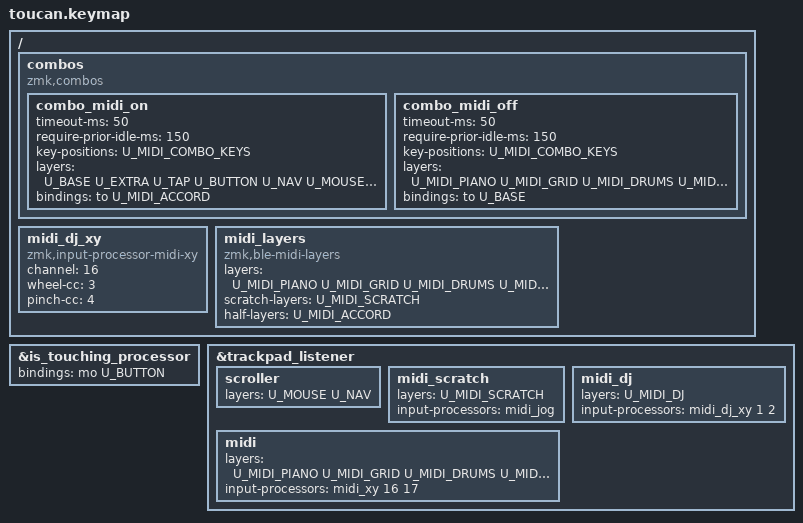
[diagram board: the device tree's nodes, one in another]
// Copyright 2021 Manna Harbour
// https://github.com/manna-harbour/miryoku

// beekeeb Toucan2 (42-key) -- Piantor/Cantor layout with an Azoteq TPS43
// multi-touch trackpad on the RIGHT half.
//
// The key matrix is identical in shape and order to the Corne: 12/12/12 plus
// six thumbs, so the stock Miryoku 42-key Corne mapping applies unchanged,
// including our outer-column Witch / Mouseless / WINDOW keys.

// Bluetooth MIDI: this board builds the zmk-ble-midi module (see
// docs/MIDI.md), which adds the MIDI layers and the midi_* behaviors.
#define MIRYOKU_MIDI
#include <behaviors/midi.dtsi>

#include "../miryoku/custom_config.h"
#include "../miryoku/mapping/42/corne.h"
#include "../miryoku/miryoku_midi.h"
#include "../miryoku/miryoku.dtsi"

// MIDI on / off: press both bottom outer pinky keys together. The same
// gesture enters (always on Accordion) and leaves (back to BASE) from any MIDI
// mode. It is the only way in or out.
//
// Positions 24 and 35 are the bottom-row outer keys (row by row: 12 top,
// 12 home, 12 bottom, 6 thumbs). Normally each one holds the WINDOW layer;
// in the MIDI modes they are notes, drums or Panic / Reset. Alone, every one
// of them still does its own job; the combo only fires when both go down
// within 50 ms. require-prior-idle-ms keeps it out of the way while you
// type or play: if any key was pressed in the last 150 ms, the two keys act
// alone immediately, so fast passages never wait on the combo and can't
// accidentally drop you out of MIDI.
//
// Combos only look at the highest active layer, hence two combos: one for
// the typing layers, one for the MIDI layers (including the held MODE layer).
#define U_MIDI_COMBO_KEYS 24 35
/ {
    combos {
        compatible = "zmk,combos";
        combo_midi_on {
            timeout-ms = <50>;
            require-prior-idle-ms = <150>;
            key-positions = <U_MIDI_COMBO_KEYS>;
            layers = <U_BASE U_EXTRA U_TAP U_BUTTON U_NAV U_MOUSE U_MEDIA U_NUM U_SYM U_FUN U_WINDOW>;
            bindings = <&to U_MIDI_ACCORD>;
        };
        combo_midi_off {
            timeout-ms = <50>;
            require-prior-idle-ms = <150>;
            key-positions = <U_MIDI_COMBO_KEYS>;
            layers = <U_MIDI_PIANO U_MIDI_GRID U_MIDI_DRUMS U_MIDI_CHORD U_MIDI_CTRL U_MIDI_DJ U_MIDI_SCRATCH U_MIDI_ACCORD U_MIDI_MODE>;
            bindings = <&to U_BASE>;
        };
    };

    // Tells the zmk-ble-midi module (and through it the status screen)
    // which layers are MIDI layers, so the screen shows key / octave /
    // velocity / channel there instead of the typing-speed graph.
    // Trackpad processor for the DJ mode (see &trackpad_listener below).
    midi_dj_xy: midi_dj_xy {
        compatible = "zmk,input-processor-midi-xy";
        #input-processor-cells = <2>;
        channel = <16>;
        wheel-cc = <3>;
        pinch-cc = <4>;
    };

    midi_layers {
        compatible = "zmk,ble-midi-layers";
        layers = <U_MIDI_PIANO U_MIDI_GRID U_MIDI_DRUMS U_MIDI_CHORD U_MIDI_CTRL U_MIDI_DJ U_MIDI_SCRATCH U_MIDI_ACCORD U_MIDI_MODE>;
        scratch-layers = <U_MIDI_SCRATCH>;
        half-layers = <U_MIDI_ACCORD>;
    };
};

// ---------------------------------------------------------------------------
// Trackpad: re-point the shield's input processors at Miryoku's layer numbers
//
// The toucan shield ships processors that reference layer indices from
// beekeeb's OWN keymap. Miryoku numbers its layers completely differently, so
// without these overrides the trackpad silently drives the wrong layers:
//
//   index:  0 BASE  1 EXTRA  2 TAP  3 BUTTON  4 NAV  5 MOUSE
//           6 MEDIA  7 NUM   8 SYM  9 FUN    10 WINDOW
//           11-19 MIDI: PIANO GRID DRUMS CHORD CTRL DJ SCRATCH ACCORD MODE
//
// Everything else in the shield is already macOS-correct and left alone:
// the zoom mapper sends Cmd+- / Cmd+= and the three-finger swipes send
// Ctrl+Cmd+arrows (Mission Control / move between Spaces).
// ---------------------------------------------------------------------------

// Touching the pad held layer 4. In beekeeb's keymap that is their click
// layer; in Miryoku layer 4 is NAV, so merely resting a finger on the
// trackpad would have swapped the whole right hand to arrows and clipboard.
// BUTTON (3) is Miryoku's mouse-button layer -- while touching the pad the
// thumbs become left / right / middle click, which is the intended effect.
&is_touching_processor {
    bindings = <&mo U_BUTTON>;
};

// "Scroll instead of move" was bound to layers 1 and 2. In Miryoku those are
// the alternate alpha layouts (EXTRA / TAP), so the trackpad would have turned
// into a scroll wheel whenever a different base layout was locked on. Point it
// at the two layers where scrolling is what you actually want.
&trackpad_listener {
    scroller {
        layers = <U_MOUSE U_NAV>;
    };

    // On every MIDI layer the trackpad is a MIDI controller instead of a
    // mouse (the trackpad driver tells the gestures apart):
    //   one finger              XY pad: left/right CC 16, up/down CC 17
    //   two fingers up/down     velocity slider for every note key
    //   pinch                   CC 18 (spread = up)
    // The processor swallows every trackpad event there, so the cursor stays
    // put and touching the pad does not pull in the BUTTON layer. Tuning
    // (travel, direction, pinch CC) is on &midi_xy, see docs/MIDI.md.
    // DJ mode: same gestures, but every one is a knob on MIDI channel 16 so
    // djay's MIDI Learn can take them (no velocity slider, there are no notes
    // to play): one finger X = CC 1 (crossfader), Y = CC 2, two fingers up/
    // down = CC 3, pinch = CC 4. Listed first so it wins on the DJ layer.
    // Scratch mode: the trackpad is the scratch deck's jog wheel. Finger down
    // = platter touch (grab the record), slide left/right = jog, lift = let
    // go. All on channel 16 like the DJ layer. See &midi_jog for tuning
    // (divisor, invert, encoding).
    midi_scratch {
        layers = <U_MIDI_SCRATCH>;
        input-processors = <&midi_jog>;
    };

    midi_dj {
        layers = <U_MIDI_DJ>;
        input-processors = <&midi_dj_xy 1 2>;
    };

    midi {
        layers = <U_MIDI_PIANO U_MIDI_GRID U_MIDI_DRUMS U_MIDI_CHORD U_MIDI_CTRL U_MIDI_ACCORD U_MIDI_MODE>;
        input-processors = <&midi_xy 16 17>;
    };
};
